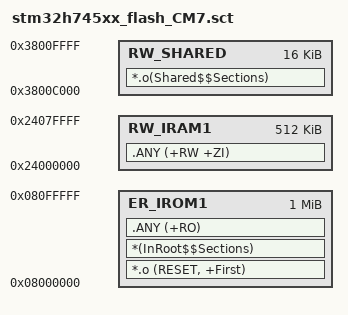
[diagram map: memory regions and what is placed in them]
; *************************************************************
; *** Scatter-Loading Description File generated by uVision ***
; *************************************************************

LR_IROM1 0x08000000 0x00100000  {    ; load region size_region
  ER_IROM1 0x08000000 0x00100000  {  ; load address = execution address
    *.o (RESET, +First)
    *(InRoot$$Sections)
    .ANY (+RO)
  }
;  RW_IRAM2 0x20000000 0x00020000 { ; RW (DTCM 128K)
;    .ANY (+RW +ZI)
;  }
  RW_IRAM1 0x24000000 0x00080000 {  ; RW data (AXI SRAM, 512K)
    .ANY (+RW +ZI)
  }
;  RW_IRAM3 0x38800000 0x00001000 { ; RW (Backup RAM 32K)
;    .ANY (+RW +ZI)
;  }
  RW_SHARED 0x3800C000 0x00004000 { ; RW shared memory (SRAM4 16K)
    *.o(Shared$$Sections)
  }
}
